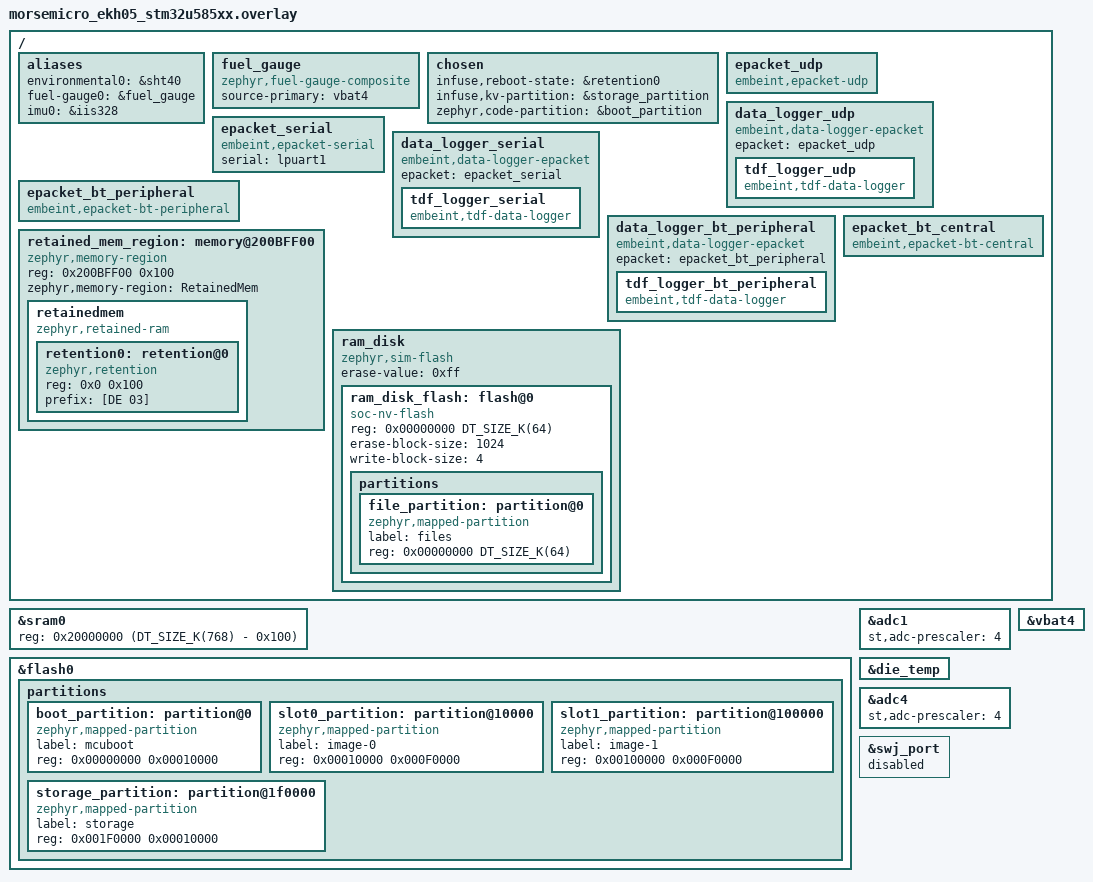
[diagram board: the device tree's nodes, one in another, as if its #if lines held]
/*
 * Copyright (c) 2026 Embeint Holdings Pty Ltd
 * SPDX-License-Identifier: FSL-1.1-ALv2
 *
 * Morse Micro MM6108-EKH05 and MM8108-EKH05 evaluation kits
 */

/ {
	aliases {
		environmental0 = &sht40;
		fuel-gauge0 = &fuel_gauge;
		imu0 = &iis328;
	};

	/* Battery voltage measured on the VBAT pin.
	 * On this board it is a regulated 3.3V rail, not the raw input.
	 */
	fuel_gauge: fuel_gauge {
		compatible = "zephyr,fuel-gauge-composite";
		source-primary = <&vbat4>;
	};

	chosen {
		infuse,reboot-state = &retention0;
		infuse,kv-partition = &storage_partition;
#ifdef INFUSE_IS_BOOTLOADER
		zephyr,code-partition = &boot_partition;
#else
		zephyr,code-partition = &slot0_partition;
#endif /* INFUSE_IS_BOOTLOADER */
	};

	epacket_udp: epacket_udp {
		compatible = "embeint,epacket-udp";
	};

	data_logger_udp: data_logger_udp {
		compatible = "embeint,data-logger-epacket", "embeint,data-logger";
		epacket = <&epacket_udp>;

		tdf_logger_udp: tdf_logger_udp {
			compatible = "embeint,tdf-data-logger";
		};
	};

	epacket_serial: epacket_serial {
		compatible = "embeint,epacket-serial";
		serial = <&lpuart1>;
	};

	data_logger_serial: data_logger_serial {
		compatible = "embeint,data-logger-epacket", "embeint,data-logger";
		epacket = <&epacket_serial>;

		tdf_logger_serial: tdf_logger_serial {
			compatible = "embeint,tdf-data-logger";
		};
	};

	/* Blue-NRG2 controller does not support extended advertising, so we can only
	 * use ePacket data over GATT.
	 */
	epacket_bt_peripheral: epacket_bt_peripheral {
		compatible = "embeint,epacket-bt-peripheral";
	};

	data_logger_bt_peripheral: data_logger_bt_peripheral {
		compatible = "embeint,data-logger-epacket", "embeint,data-logger";
		epacket = <&epacket_bt_peripheral>;

		tdf_logger_bt_peripheral: tdf_logger_bt_peripheral {
			compatible = "embeint,tdf-data-logger";
		};
	};

	epacket_bt_central: epacket_bt_central {
		compatible = "embeint,epacket-bt-central";
	};

	/* End of SRAM */
	retained_mem_region: memory@200BFF00 {
		compatible = "zephyr,memory-region", "mmio-sram";
		reg = <0x200BFF00 0x100>;
		zephyr,memory-region = "RetainedMem";
		status = "okay";

		retainedmem {
			compatible = "zephyr,retained-ram";
			status = "okay";
			#address-cells = <1>;
			#size-cells = <1>;

			retention0: retention@0 {
				compatible = "zephyr,retention";
				status = "okay";
				reg = <0x0 0x100>;
				prefix = [DE 03];
			};
		};
	};
};

#ifndef INFUSE_IS_BOOTLOADER
/* RAM backed storage for patch files, internal flash is consumed by the image slots */
/ {
	ram_disk: ram_disk {
		compatible = "zephyr,sim-flash";
		#address-cells = <1>;
		#size-cells = <1>;
		erase-value = <0xff>;

		ram_disk_flash: flash@0 {
			compatible = "soc-nv-flash";
			reg = <0x00000000 DT_SIZE_K(64)>;
			erase-block-size = <1024>;
			write-block-size = <4>;

			partitions {
				ranges;
				#address-cells = <1>;
				#size-cells = <1>;

				file_partition: partition@0 {
					compatible = "zephyr,mapped-partition";
					label = "files";
					reg = <0x00000000 DT_SIZE_K(64)>;
				};
			};
		};
	};
};
#endif /* INFUSE_IS_BOOTLOADER */

&sram0 {
	reg = <0x20000000 (DT_SIZE_K(768) - 0x100)>;
};

/* Replace the board storage partition with an MCUboot compatible layout */
/delete-node/ &storage_partition;

&flash0 {
	partitions {
		/delete-property/ compatible;
		ranges;
		#address-cells = <1>;
		#size-cells = <1>;

		boot_partition: partition@0 {
			compatible = "zephyr,mapped-partition";
			label = "mcuboot";
			reg = <0x00000000 0x00010000>;
		};
		/* HaLow driver + chip firmware requires ~1MB of application flash */
		slot0_partition: partition@10000 {
			compatible = "zephyr,mapped-partition";
			label = "image-0";
			reg = <0x00010000 0x000F0000>;
		};
		slot1_partition: partition@100000 {
			compatible = "zephyr,mapped-partition";
			label = "image-1";
			reg = <0x00100000 0x000F0000>;
		};
		storage_partition: partition@1f0000 {
			compatible = "zephyr,mapped-partition";
			label = "storage";
			reg = <0x001F0000 0x00010000>;
		};
	};
};

/* Internal CPU temperature monitoring */
&adc1 {
	status = "okay";
	st,adc-prescaler = <4>;
};
&die_temp {
	status = "okay";
};

/* Battery voltage monitoring for the fuel gauge */
&adc4 {
	status = "okay";
	st,adc-prescaler = <4>;
};
&vbat4 {
	status = "okay";
};

/* Keep the SWD pins active on the evaluation kits. With CONFIG_PM=y and
 * CONFIG_DEBUG=n, Zephyr otherwise switches them to analog at boot, which
 * prevents the debugger attaching to a running device.
 */
&swj_port {
	status = "disabled";
};
